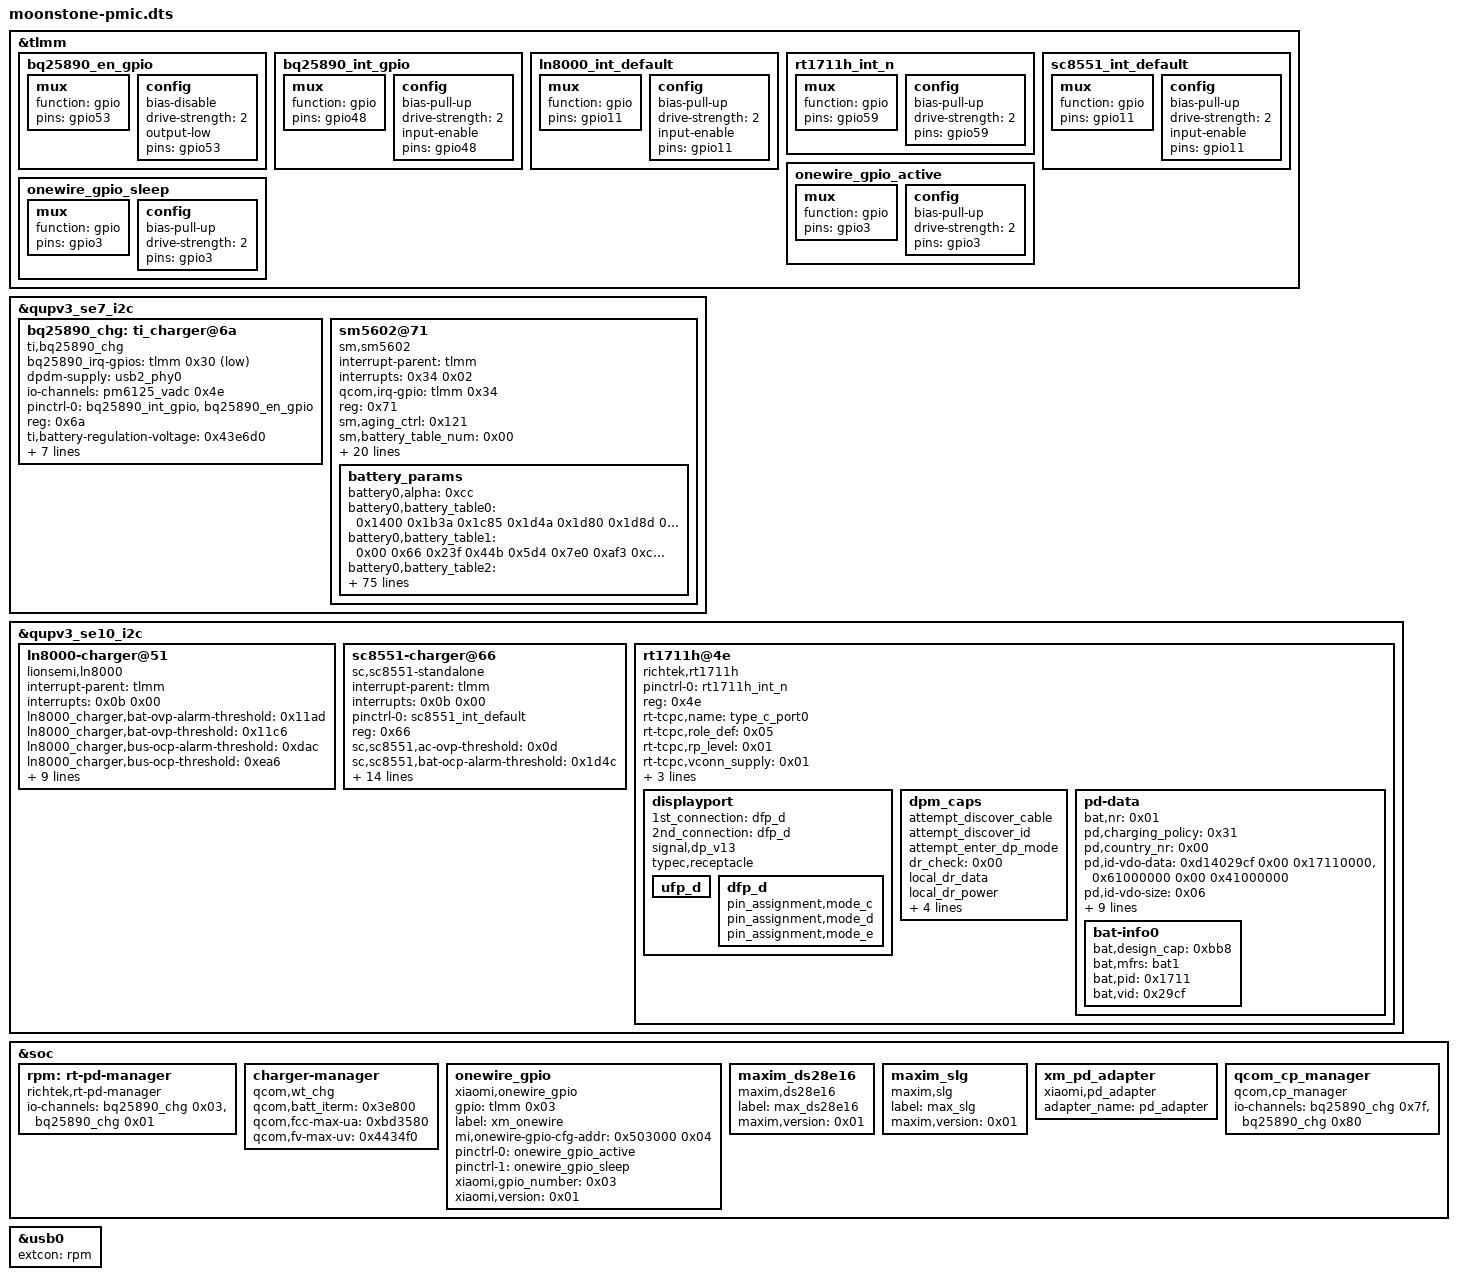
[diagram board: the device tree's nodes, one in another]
&tlmm {
	bq25890_en_gpio: bq25890_en_gpio {
		mux {
			function = "gpio";
			pins = "gpio53";
		};

		config {
			bias-disable;
			drive-strength = <2>;
			output-low;
			pins = "gpio53";
		};
	};

	bq25890_int_gpio: bq25890_int_gpio {
		mux {
			function = "gpio";
			pins = "gpio48";
		};

		config {
			bias-pull-up;
			drive-strength = <2>;
			input-enable;
			pins = "gpio48";
		};
	};

	ln8000_int_default: ln8000_int_default {
		mux {
			function = "gpio";
			pins = "gpio11";
		};

		config {
			bias-pull-up;
			drive-strength = <2>;
			input-enable;
			pins = "gpio11";
		};
	};

	rt1711h_int_n: rt1711h_int_n {
		mux {
			function = "gpio";
			pins = "gpio59";
		};

		config {
			bias-pull-up;
			drive-strength = <2>;
			pins = "gpio59";
		};
	};

	sc8551_int_default: sc8551_int_default {
		mux {
			function = "gpio";
			pins = "gpio11";
		};

		config {
			bias-pull-up;
			drive-strength = <2>;
			input-enable;
			pins = "gpio11";
		};
	};

	onewire_gpio_active: onewire_gpio_active {
		mux {
			function = "gpio";
			pins = "gpio3";
		};

		config {
			bias-pull-up;
			drive-strength = <2>;
			pins = "gpio3";
		};
	};

	onewire_gpio_sleep: onewire_gpio_sleep {
		mux {
			function = "gpio";
			pins = "gpio3";
		};

		config {
			bias-pull-up;
			drive-strength = <2>;
			pins = "gpio3";
		};
	};
};

&qupv3_se7_i2c {
	status = "ok";

	bq25890_chg: ti_charger@6a {
		#io-channel-cells = <1>;
		bq25890_irq-gpios = <&tlmm 0x30 0x01>;
		compatible = "ti,bq25890_chg";
		dpdm-supply = <&usb2_phy0>;
		io-channel-names = "quiet_therm";
		io-channels = <&pm6125_vadc 0x4e>;
		pinctrl-0 = <&bq25890_int_gpio &bq25890_en_gpio>;
		pinctrl-names = "default";
		reg = <0x6a>;
		ti,battery-regulation-voltage = <0x43e6d0>;
		ti,boost-max-current = <0x192d50>;
		ti,boost-voltage = <0x4c4b40>;
		ti,charge-current = <0x2dc6c0>;
		ti,minimum-sys-voltage = <0x36ee80>;
		ti,precharge-current = <0x1f400>;
		ti,termination-current = <0x30d40>;
		ti,thermal-regulation-threshold = <0x78>;
	};

	sm5602@71 {
		compatible = "sm,sm5602";
		interrupt-parent = <&tlmm>;
		interrupts = <0x34 0x02>;
		qcom,irq-gpio = <&tlmm 0x34 0x00>;
		reg = <0x71>;
		sm,aging_ctrl = <0x121>;
		sm,battery_table_num = <0x00>;
		sm,cycle_cfg = <0x7000>;
		sm,en_batt_det;
		sm,en_temp_ex;
		sm,fg_irq_set = <0x7ff>;
		sm,iocv_man_mode;
		sm,low_soc1 = <0x01>;
		sm,low_soc2 = <0x0f>;
		sm,misc = <0x800>;
		sm,param_version = <0x01>;
		sm,rsns = <0x00>;
		sm,rtrace = <0x1f40>;
		sm,shutdown-delay-enable;
		sm,soc_decimal_rate = <0x00 0x20 0x0a 0x1e 0x14 0x1c 0x1e 0x1c 0x28 0x1c 0x32 0x1c 0x3c 0x1c 0x46 0x1c 0x50 0x1c 0x5a 0x1a 0x5f 0x0a 0x63 0x05>;
		sm,t_h_alarm_ex = <0x9245>;
		sm,t_h_alarm_in = <0x01>;
		sm,t_l_alarm_ex = <0xd3d8>;
		sm,t_l_alarm_in = <0x36>;
		sm,v_h_alarm = <0x1162>;
		sm,v_l_alarm = <0xd48>;

		battery_params {
			// battery,id = 0;
			battery0,alpha = <0xcc>;
			battery0,battery_table0 = <0x1400 0x1b3a 0x1c85 0x1d4a 0x1d80 0x1d8d 0x1d95 0x1dad 0x1dfa 0x1e40 0x1e79 0x1eb6 0x1f0d 0x1f6c 0x1fb6 0x1feb 0x204d 0x20f2 0x21a7 0x2225 0x227a 0x2316 0x235d 0x24cc>;
			battery0,battery_table1 = <0x00 0x66 0x23f 0x44b 0x5d4 0x7e0 0xaf3 0xcff 0x13a6 0x1b53 0x2300 0x2aae 0x325b 0x3779 0x3a08 0x3c97 0x41b5 0x4963 0x5110 0x562e 0x59c3 0x60ed 0x6400 0x64e6>;
			battery0,battery_table2 = <0x1720 0x1214 0x1011 0xe0f 0xc0d 0xc0c 0xb0b 0xb0b>;
			battery0,battery_type = <0x1162 0x00 0x26e1>;
			battery0,beta = <0x25>;
			battery0,curr_offset = <0x00>;
			battery0,curr_slope = <0x8580>;
			battery0,ext_temp_cal = <0x00 0x02 0x01 0x02 0x01 0x01 0x02 0x03 0x02 0x03>;
			battery0,max_voltage_uv = <0x43e6d0>;
			battery0,mix_value = <0x03>;
			battery0,param_version = <0x09>;
			battery0,rs = <0x5f>;
			battery0,rs_value = <0x50 0x10a 0x3800 0x48>;
			battery0,tem_poff = <0xd48 0x64>;
			battery0,temp_cal = <0 6 1 11 (-1) 0 6 1 9 1>;
			battery0,temp_offset = <0 11 1 0 8 (-1)>;
			battery0,temp_std = <0x19>;
			battery0,thermal_table = <0x3b3a 0x3516 0x2f05 0x28f4 0x2323 0x1d80 0x1804 0x12e1 0xda7 0x8b3 0x3d6 0xf6f2 0xf273 0xee03 0xe9d0 0xe5c7 0xe1e2 0xde2c 0xda98 0xd727 0xd3d8 0xd0b2 0xcdac 0xcac8 0xc806 0xc55c 0xc2d0 0xc069 0xbe17 0xbbe1 0xb9c6 0xb7c0 0xb5d3 0xb400 0xb242 0xb092 0xaefd 0xad7c 0xac06 0xaaa6 0xa953 0xa814 0xa6de 0xa5be 0xa4a5 0xa39c 0xa2a1 0xa1b1 0xa0cb 0x9ff3 0x9f23 0x9e59 0x9d9a 0x9ce7 0x9c3b 0x9b95 0x9af7 0x9a62 0x99d2 0x994b 0x98cb 0x984e 0x97d6 0x9765 0x96fa 0x9693 0x9631 0x95d3 0x9579 0x9523 0x94cf 0x9481 0x9435 0x93ec 0x93a6 0x9364 0x9325 0x92ea 0x92b1 0x927b 0x9245 0x9212 0x91e1 0x91b2 0x9185 0x915a 0x9132 0x910b 0x90e6 0x90c2 0x90a0 0x907e 0x905e 0x9040 0x9022 0x9006 0x8fea 0x8fd0 0x8fb7 0x8fa0 0x8f8a>;
			battery0,topoff_soc = <0x07 0x12c 0x64>;
			battery0,vit_period = <0x315a>;
			battery0,volt_cal = <0x8000>;
			// battery,id = 1
			battery1,alpha = <0xcc>;
			battery1,battery_table0 = <0x1400 0x1b3e 0x1c27 0x1ce5 0x1d63 0x1d89 0x1d90 0x1d95 0x1de9 0x1e2d 0x1e75 0x1eb1 0x1f02 0x1f4f 0x1f8a 0x1fdc 0x2041 0x20e5 0x2199 0x2218 0x2271 0x230f 0x234c 0x24cc>;
			battery1,battery_table1 = <0x00 0x66 0x191 0x323 0x4b5 0x6cd 0x8e5 0xafe 0x11cc 0x19a7 0x2181 0x295c 0x3136 0x3672 0x3911 0x3baf 0x40eb 0x48c6 0x50a0 0x55dd 0x5987 0x60db 0x6400 0x64e6>;
			battery1,battery_table2 = <0x1b28 0x1417 0x1113 0xf10 0xd0e 0xc0d 0xc0c 0xb0b>;
			battery1,battery_type = <0x1162 0x00 0x26d7>;
			battery1,beta = <0x25>;
			battery1,curr_offset = <0x00>;
			battery1,curr_slope = <0x8580>;
			battery1,ext_temp_cal = <0x00 0x02 0x01 0x02 0x01 0x01 0x02 0x03 0x02 0x03>;
			battery1,max_voltage_uv = <0x43e6d0>;
			battery1,mix_value = <0x03>;
			battery1,param_version = <0x09>;
			battery1,rs = <0x5f>;
			battery1,rs_value = <0x50 0x10a 0x3800 0x48>;
			battery1,tem_poff = <0xd48 0x64>;
			battery1,temp_cal = <0 6 1 11 (-1) 0 6 1 9 1>;
			battery1,temp_offset = <0 11 1 0 8 (-1)>;
			battery1,temp_std = <0x19>;
			battery1,thermal_table = <0x3b3a 0x3516 0x2f05 0x28f4 0x2323 0x1d80 0x1804 0x12e1 0xda7 0x8b3 0x3d6 0xf6f2 0xf273 0xee03 0xe9d0 0xe5c7 0xe1e2 0xde2c 0xda98 0xd727 0xd3d8 0xd0b2 0xcdac 0xcac8 0xc806 0xc55c 0xc2d0 0xc069 0xbe17 0xbbe1 0xb9c6 0xb7c0 0xb5d3 0xb400 0xb242 0xb092 0xaefd 0xad7c 0xac06 0xaaa6 0xa953 0xa814 0xa6de 0xa5be 0xa4a5 0xa39c 0xa2a1 0xa1b1 0xa0cb 0x9ff3 0x9f23 0x9e59 0x9d9a 0x9ce7 0x9c3b 0x9b95 0x9af7 0x9a62 0x99d2 0x994b 0x98cb 0x984e 0x97d6 0x9765 0x96fa 0x9693 0x9631 0x95d3 0x9579 0x9523 0x94cf 0x9481 0x9435 0x93ec 0x93a6 0x9364 0x9325 0x92ea 0x92b1 0x927b 0x9245 0x9212 0x91e1 0x91b2 0x9185 0x915a 0x9132 0x910b 0x90e6 0x90c2 0x90a0 0x907e 0x905e 0x9040 0x9022 0x9006 0x8fea 0x8fd0 0x8fb7 0x8fa0 0x8f8a>;
			battery1,topoff_soc = <0x07 0x12c 0x64>;
			battery1,vit_period = <0x315a>;
			battery1,volt_cal = <0x8000>;
			// battery,id = 2
			battery2,alpha = <0xcc>;
			battery2,battery_table0 = <0x1400 0x1b3a 0x1c85 0x1d4a 0x1d80 0x1d8d 0x1d95 0x1dad 0x1dfa 0x1e40 0x1e79 0x1eb6 0x1f0d 0x1f6c 0x1fb6 0x1feb 0x204d 0x20f2 0x21a7 0x2225 0x227a 0x2316 0x235d 0x24cc>;
			battery2,battery_table1 = <0x00 0x66 0x23f 0x44b 0x5d4 0x7e0 0xaf3 0xcff 0x13a6 0x1b53 0x2300 0x2aae 0x325b 0x3779 0x3a08 0x3c97 0x41b5 0x4963 0x5110 0x562e 0x59c3 0x60ed 0x6400 0x64e6>;
			battery2,battery_table2 = <0x1720 0x1214 0x1011 0xe0f 0xc0d 0xc0c 0xb0b 0xb0b>;
			battery2,battery_type = <0x1162 0x00 0x26e1>;
			battery2,beta = <0x25>;
			battery2,curr_offset = <0x00>;
			battery2,curr_slope = <0x8580>;
			battery2,ext_temp_cal = <0x00 0x02 0x01 0x02 0x01 0x01 0x02 0x03 0x02 0x03>;
			battery2,max_voltage_uv = <0x43e6d0>;
			battery2,mix_value = <0x03>;
			battery2,param_version = <0x03>;
			battery2,rs = <0x5f>;
			battery2,rs_value = <0x50 0x10a 0x3800 0x48>;
			battery2,tem_poff = <0xd48 0x64>;
			battery2,temp_cal = <0 6 1 11 (-1) 0 6 1 9 1>;
			battery2,temp_offset = <0 11 1 0 8 (-1)>;
			battery2,temp_std = <0x19>;
			battery2,thermal_table = <0x3b3a 0x3516 0x2f05 0x28f4 0x2323 0x1d80 0x1804 0x12e1 0xda7 0x8b3 0x3d6 0xf6f2 0xf273 0xee03 0xe9d0 0xe5c7 0xe1e2 0xde2c 0xda98 0xd727 0xd3d8 0xd0b2 0xcdac 0xcac8 0xc806 0xc55c 0xc2d0 0xc069 0xbe17 0xbbe1 0xb9c6 0xb7c0 0xb5d3 0xb400 0xb242 0xb092 0xaefd 0xad7c 0xac06 0xaaa6 0xa953 0xa814 0xa6de 0xa5be 0xa4a5 0xa39c 0xa2a1 0xa1b1 0xa0cb 0x9ff3 0x9f23 0x9e59 0x9d9a 0x9ce7 0x9c3b 0x9b95 0x9af7 0x9a62 0x99d2 0x994b 0x98cb 0x984e 0x97d6 0x9765 0x96fa 0x9693 0x9631 0x95d3 0x9579 0x9523 0x94cf 0x9481 0x9435 0x93ec 0x93a6 0x9364 0x9325 0x92ea 0x92b1 0x927b 0x9245 0x9212 0x91e1 0x91b2 0x9185 0x915a 0x9132 0x910b 0x90e6 0x90c2 0x90a0 0x907e 0x905e 0x9040 0x9022 0x9006 0x8fea 0x8fd0 0x8fb7 0x8fa0 0x8f8a>;
			battery2,topoff_soc = <0x07 0x12c 0x64>;
			battery2,vit_period = <0x315a>;
			battery2,volt_cal = <0x8000>;
		};
	};
};

&qupv3_se10_i2c {
	ln8000-charger@51 {
		#io-channel-cells = <1>;
		compatible = "lionsemi,ln8000";
		interrupt-parent = <&tlmm>;
		interrupts = <0x0b 0x00>;
		ln8000_charger,bat-ovp-alarm-threshold = <0x11ad>;
		ln8000_charger,bat-ovp-threshold = <0x11c6>;
		ln8000_charger,bus-ocp-alarm-threshold = <0xdac>;
		ln8000_charger,bus-ocp-threshold = <0xea6>;
		ln8000_charger,bus-ovp-alarm-threshold = <0x2af8>;
		ln8000_charger,bus-ovp-threshold = <0x32c8>;
		ln8000_charger,ext_ovp_ctrl = <0x00>;
		ln8000_charger,ntc-alarm-cfg = <0xe2>;
		ln8000_charger,tbat-mon-disable;
		ln8000_charger,tbus-mon-disable;
		ln8000_charger,tdie-prot-disable;
		pinctrl-0 = <&ln8000_int_default>;
		pinctrl-names = "default";
		reg = <0x51>;
	};

	sc8551-charger@66 {
		#io-channel-cells = <1>;
		compatible = "sc,sc8551-standalone";
		interrupt-parent = <&tlmm>;
		interrupts = <0x0b 0x00>;
		pinctrl-0 = <&sc8551_int_default>;
		pinctrl-names = "default";
		reg = <0x66>;
		sc,sc8551,ac-ovp-threshold = <0x0d>;
		sc,sc8551,bat-ocp-alarm-threshold = <0x1d4c>;
		sc,sc8551,bat-ocp-threshold = <0x1f40>;
		sc,sc8551,bat-ovp-alarm-threshold = <0x1130>;
		sc,sc8551,bat-ovp-threshold = <0x11df>;
		sc,sc8551,bat-therm-disable = <0x00>;
		sc,sc8551,bat-therm-threshold = <0x15>;
		sc,sc8551,bat-ucp-alarm-threshold = <0x7d0>;
		sc,sc8551,bus-ocp-alarm-threshold = <0xdac>;
		sc,sc8551,bus-ocp-threshold = <0xea6>;
		sc,sc8551,bus-ovp-alarm-threshold = <0x2af8>;
		sc,sc8551,bus-ovp-threshold = <0x2ee0>;
		sc,sc8551,bus-therm-disable = <0x00>;
		sc,sc8551,bus-therm-threshold = <0x15>;
		sc,sc8551,die-therm-threshold = <0x7d>;
		sc,sc8551,sense-resistor-mohm = <0x05>;
	};

	rt1711h@4e {
		compatible = "richtek,rt1711h";
		pinctrl-0 = <&rt1711h_int_n>;
		pinctrl-names = "default";
		reg = <0x4e>;
		rt-tcpc,name = "type_c_port0";
		rt-tcpc,role_def = <0x05>;
		rt-tcpc,rp_level = <0x01>;
		rt-tcpc,vconn_supply = <0x01>;
		rt1711pd,intr_gpio = <&tlmm 0x3b 0x00>;
		rt1711pd,intr_gpio_num = <0x3b>;
		status = "okay";
		tcpc-dual,supported_modes = <0x00>;

		displayport {
			1st_connection = "dfp_d";
			2nd_connection = "dfp_d";
			signal,dp_v13;
			typec,receptacle;

			ufp_d {
			};

			dfp_d {
				pin_assignment,mode_c;
				pin_assignment,mode_d;
				pin_assignment,mode_e;
			};
		};

		dpm_caps {
			attempt_discover_cable;
			attempt_discover_id;
			attempt_enter_dp_mode;
			dr_check = <0x00>;
			local_dr_data;
			local_dr_power;
			local_no_suspend;
			local_usb_comm;
			local_vconn_supply;
			pr_check = <0x00>;
		};

		pd-data {
			bat,nr = <0x01>;
			pd,charging_policy = <0x31>;
			pd,country_nr = <0x00>;
			pd,id-vdo-data = <0xd14029cf 0x00 0x17110000>,
				<0x61000000 0x00 0x41000000>;
			pd,id-vdo-size = <0x06>;
			pd,mfrs = "RichtekTCPC";
			pd,pid = <0x1711>;
			pd,sink-pdo-data = <0x19096>;
			pd,sink-pdo-size = <0x01>;
			pd,source-cap-ext = [cf 29 11 17 00 00 00 00 00 00 00 00 00 00 00 00 00 00 00 00 00 00 01 02 00];
			pd,source-pdo-data = <0x19096>;
			pd,source-pdo-size = <0x01>;
			pd,vid = <0x29cf>;

			bat-info0 {
				bat,design_cap = <0xbb8>;
				bat,mfrs = "bat1";
				bat,pid = <0x1711>;
				bat,vid = <0x29cf>;
			};
		};
	};
};

&soc {
	rpm: rt-pd-manager {
		#io-channel-cells = <0x01>;
		compatible = "richtek,rt-pd-manager";
		io-channel-names = "typec_cc_orientation", "typec_mode";
		io-channels = <&bq25890_chg 0x03>,
			<&bq25890_chg 0x01>;
	};

	charger-manager {
		#io-channel-cells = <1>;
		compatible = "qcom,wt_chg";
		qcom,batt_iterm = <0x3e800>;
		qcom,fcc-max-ua = <0xbd3580>;
		qcom,fv-max-uv = <0x4434f0>;
		status = "okay";
	};

	onewire_gpio {
		compatible = "xiaomi,onewire_gpio";
		gpio = <&tlmm 0x03 0x00>;
		label = "xm_onewire";
		mi,onewire-gpio-cfg-addr = <0x503000 0x04>;
		pinctrl-0 = <&onewire_gpio_active>;
		pinctrl-1 = <&onewire_gpio_sleep>;
		pinctrl-names = "onewire_active", "onewire_sleep";
		status = "ok";
		xiaomi,gpio_number = <0x03>;
		xiaomi,version = <0x01>;
	};

	maxim_ds28e16 {
		compatible = "maxim,ds28e16";
		label = "max_ds28e16";
		maxim,version = <0x01>;
		status = "ok";
	};

	maxim_slg {
		compatible = "maxim,slg";
		label = "max_slg";
		maxim,version = <0x01>;
		status = "ok";
	};

	xm_pd_adapter {
		adapter_name = "pd_adapter";
		compatible = "xiaomi,pd_adapter";
	};

	qcom_cp_manager {
		compatible = "qcom,cp_manager";
		io-channel-names = "apdo_max_volt", "apdo_max_curr";
		io-channels = <&bq25890_chg 0x7f>,
			<&bq25890_chg 0x80>;
		status = "okay";
	};
};

&usb0 {
	extcon = <&rpm>;
};
